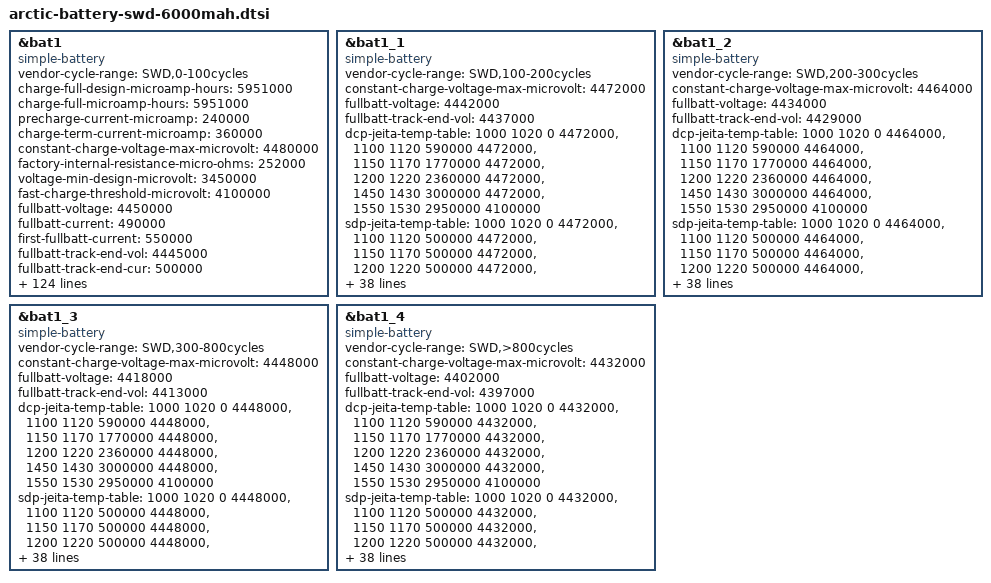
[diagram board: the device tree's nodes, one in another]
/* SWD aging 0--100 */
&bat1 {
	compatible = "simple-battery";
	status = "okay";
	vendor-cycle-range = "SWD,0-100cycles";
	charge-full-design-microamp-hours = <5951000>;
	charge-full-microamp-hours = <5951000>;
	precharge-current-microamp = <240000>;
	charge-term-current-microamp = <360000>;
	constant-charge-voltage-max-microvolt = <4480000>;
	factory-internal-resistance-micro-ohms = <252000>;
	voltage-min-design-microvolt = <3450000>;

	fast-charge-threshold-microvolt = <4100000>;
	fullbatt-voltage = <4450000>;
	fullbatt-current = <490000>;
	first-fullbatt-current = <550000>;
	fullbatt-track-end-vol = <4445000>;
	fullbatt-track-end-cur = <500000>;
	first-calib-voltage = <3580000>;
	first-calib-capacity = <50>;
	batt-ovp-threshold-microvolt = <4750000>;
	shutdown-voltage = <3150000>; //软件UVLO关机电压

	voltage-temp-table = <1119814 800>, <1007626 850>, <897107 900>,
				<791150 950>, <692012 1000>, <601214 1050>,
				<519546 1100>, <447188 1150>, <383853 1200>,
				<328947 1250>, <281696 1300>, <241249 1350>,
				<206756 1400>, <177412 1450>, <152480 1500>,
				<131307 1550>, <113324 1600>, <98032 1650>;

	temp-advance-fullcap-table = <50 100>, <25 100>, <10 100>, <0 100>,
		<(-10) 100>, <(-20) 100>;

	bcl-vbat-thres-celsius = <(-10)>, <0>, <10>, <25>, <45>;
	bcl-vbat-h-thres-0 = <3500>, <3400>;
	bcl-vbat-l-thres-0 = <3300>, <3200>;
	bcl-vbat-h-thres-1 = <3500>, <3400>;
	bcl-vbat-l-thres-1 = <3300>, <3200>;
	bcl-vbat-h-thres-2 = <3500>, <3400>;
	bcl-vbat-l-thres-2 = <3300>, <3200>;
	bcl-vbat-h-thres-3 = <3500>, <3400>;
	bcl-vbat-l-thres-3 = <3300>, <3200>;
	bcl-vbat-h-thres-4 = <3500>, <3400>;
	bcl-vbat-l-thres-4 = <3300>, <3200>;

	charge-sdp-current-microamp = <500000 500000>;
	charge-dcp-current-microamp = <2940000 1500000>;
	charge-cdp-current-microamp = <900000 900000>;
	charge-unknown-current-microamp = <1000000 1000000>;
	charge-fchg-current-microamp = <3000000 2000000>;
	charge-flash-current-microamp = <4900000 2700000>;
	charge-wl-bpp-current-microamp = <1000000 1000000>;
	charge-wl-epp-current-microamp = <2000000 1000000>;

	cap-calib-energy-density-ocv-table = <3400000 3690000>, <3890000 4480000>;

	dcp-jeita-temp-table = <1000 1020 0 4480000>, <1100 1120 590000 4480000>,
		<1150 1170 1770000 4480000>, <1200 1220 2360000 4480000>,
		<1450 1430 3000000 4480000>, <1550 1530 2950000 4100000>;
	sdp-jeita-temp-table = <1000 1020 0 4480000>, <1100 1120 500000 4480000>,
		<1150 1170 500000 4480000>, <1200 1220 500000 4480000>,
		<1450 1430 500000 4480000>, <1550 1530 500000 4100000>;
	cdp-jeita-temp-table = <1000 1020 0 4480000>, <1100 1120 590000 4480000>,
		<1150 1170 900000 4480000>, <1200 1220 900000 4480000>,
		<1450 1430 900000 4480000>, <1550 1530 900000 4100000>;
	unknown-jeita-temp-table = <1000 1020 0 4480000>, <1100 1120 590000 4480000>,
		<1150 1170 1000000 4480000>, <1200 1220 1000000 4480000>,
		<1450 1430 1000000 4480000>, <1550 1530 1000000 4100000>;
	fchg-jeita-temp-table = <1000 1020 0 4480000>, <1100 1120 590000 4480000>,
		<1150 1170 1770000 4480000>, <1200 1220 2360000 4480000>,
		<1450 1430 3000000 4480000>, <1550 1530 2950000 4100000>;
	flash-jeita-temp-table = <1000 1020 0 4480000>, <1100 1120 590000 4480000>,
		<1150 1170 1770000 4480000>, <1200 1220 2360000 4480000>,
		<1450 1430 3000000 4480000>, <1550 1530 2950000 4100000>;
	wl-bpp-jeita-temp-table = <1000 1020 0 4480000>, <1100 1120 500000 4480000>,
		<1150 1170 500000 4480000>, <1200 1220 500000 4480000>,
		<1450 1430 1000000 4480000>, <1550 1530 500000 4100000>;
	wl-epp-jeita-temp-table = <1000 1020 0 4480000>, <1100 1120 500000 4480000>,
		<1150 1170 500000 4480000>, <1200 1220 500000 4480000>,
		<1450 1430 2000000 4480000>, <1550 1530 500000 4100000>;


	bat-temp = <(-20)>, <(-10)>, <0>, <10>, <25>, <45>;

	/* temp-fcc */
	temp-fcc-fcc = <5438000>, <5611000>, <5841000>, <5904000>, <5951000>, <5891000>;

	/* temp-hc */
	temp-hc-hc = <20>, <20>, <20>, <10>, <10>, <10>;

	/* temp-zero-point-voltage */
	temp-zpvol-zpvol = <3430000>, <3430000>, <3430000>, <3450000>, <3450000>, <3450000>;
	/* temp-abs-zero-point-voltage */
	temp-abs-zpvol-zpvol = <3425000>, <3425000>, <3425000>, <3445000>, <3445000>, <3445000>;
	/* temp-bat-voltage */
	temp-batvol-batvol = <3570000>, <3570000>, <3570000>, <3580000>, <3580000>, <3580000>;

	/* cap-temp-ocv */
	cap-temp-ocv-cap = <100>, <99>, <98>, <97>, <96>, <95>, <94>, <93>, <92>, <91>, <90>,
			<89>, <88>, <87>, <86>, <85>, <84>, <83>, <82>, <81>, <80>,
			<79>, <78>, <77>, <76>, <75>, <74>, <73>, <72>, <71>, <70>,
			<69>, <68>, <67>, <66>, <65>, <64>, <63>, <62>, <61>, <60>,
			<59>, <58>, <57>, <56>, <55>, <54>, <53>, <52>, <51>, <50>,
			<49>, <48>, <47>, <46>, <45>, <44>, <43>, <42>, <41>, <40>,
			<39>, <38>, <37>, <36>, <35>, <34>, <33>, <32>, <31>, <30>,
			<29>, <28>, <27>, <26>, <25>, <24>, <23>, <22>, <21>, <20>,
			<19>, <18>, <17>, <16>, <15>, <14>, <13>, <12>, <11>, <10>,
			<9>, <8>, <7>, <6>, <5>, <4>, <3>, <2>, <1>, <0>;
	cap-temp-ocv-ocv = <
			/* -20 celsius */
			4422000 4400000 4382000 4365000 4350000 4336000 4322000 4310000 4296000 4284000
			4271000 4259000 4247000 4236000 4224000 4213000 4202000 4191000 4181000 4170000
			4160000 4150000 4140000 4130000 4119000 4109000 4099000 4088000 4078000 4067000
			4056000 4046000 4035000 4024000 4013000 4002000 3992000 3981000 3971000 3961000
			3951000 3941000 3931000 3922000 3912000 3904000 3896000 3888000 3880000 3872000
			3864000 3858000 3850000 3844000 3838000 3832000 3826000 3820000 3815000 3810000
			3806000 3802000 3798000 3794000 3790000 3788000 3784000 3782000 3778000 3775000
			3772000 3768000 3764000 3761000 3756000 3752000 3748000 3742000 3738000 3732000
			3726000 3718000 3711000 3703000 3694000 3686000 3676000 3665000 3655000 3644000
			3632000 3620000 3608000 3596000 3584000 3573000 3562000 3548000 3532000 3516000
			3500000
			/* -10 celsius */
			4426000 4408000 4392000 4378000 4365000 4352000 4340000 4328000 4315000 4303000
			4290000 4278000 4266000 4254000 4242000 4231000 4220000 4208000 4198000 4187000
			4176000 4166000 4156000 4145000 4134000 4124000 4113000 4102000 4092000 4081000
			4070000 4060000 4050000 4038000 4028000 4018000 4006000 3996000 3986000 3975000
			3964000 3954000 3943000 3932000 3922000 3913000 3904000 3894000 3886000 3878000
			3870000 3863000 3856000 3849000 3843000 3837000 3832000 3826000 3821000 3816000
			3811000 3807000 3803000 3799000 3795000 3792000 3789000 3787000 3784000 3782000
			3780000 3778000 3776000 3774000 3771000 3768000 3766000 3762000 3759000 3755000
			3750000 3745000 3739000 3732000 3724000 3715000 3704000 3690000 3676000 3659000
			3641000 3623000 3605000 3587000 3569000 3551000 3533000 3517000 3503000 3489000
			3473000
			/* 0 celsius */
			4427000 4410000 4396000 4382000 4370000 4358000 4346000 4332000 4320000 4307000
			4294000 4282000 4268000 4256000 4244000 4232000 4220000 4208000 4196000 4186000
			4174000 4164000 4152000 4142000 4130000 4120000 4108000 4098000 4086000 4076000
			4065000 4054000 4044000 4034000 4024000 4014000 4004000 3994000 3984000 3974000
			3964000 3954000 3944000 3932000 3921000 3910000 3898000 3888000 3880000 3872000
			3864000 3856000 3850000 3844000 3838000 3832000 3828000 3822000 3818000 3814000
			3809000 3805000 3801000 3798000 3794000 3792000 3788000 3786000 3784000 3782000
			3781000 3780000 3778000 3776000 3775000 3773000 3770000 3768000 3765000 3761000
			3756000 3751000 3744000 3738000 3730000 3718000 3704000 3686000 3665000 3641000
			3618000 3595000 3572000 3552000 3536000 3520000 3504000 3488000 3471000 3450000
			3418000
			/* 10 celsius */
			4432000 4416000 4402000 4388000 4376000 4363000 4350000 4338000 4325000 4312000
			4299000 4286000 4274000 4261000 4248000 4236000 4224000 4212000 4200000 4189000
			4178000 4166000 4155000 4144000 4133000 4122000 4110000 4100000 4088000 4078000
			4067000 4056000 4046000 4036000 4026000 4016000 4006000 3996000 3988000 3978000
			3968000 3960000 3950000 3939000 3928000 3916000 3904000 3892000 3882000 3874000
			3866000 3858000 3852000 3846000 3840000 3835000 3830000 3825000 3820000 3816000
			3812000 3808000 3804000 3801000 3798000 3794000 3792000 3790000 3787000 3785000
			3784000 3782000 3781000 3779000 3778000 3776000 3774000 3771000 3768000 3764000
			3759000 3754000 3750000 3744000 3739000 3732000 3723000 3712000 3698000 3680000
			3659000 3632000 3604000 3581000 3564000 3548000 3532000 3516000 3496000 3465000
			3412000
			/* 25 celsius */
			4432000 4414000 4400000 4386000 4373000 4360000 4348000 4334000 4322000 4308000
			4295000 4282000 4270000 4256000 4244000 4232000 4220000 4208000 4196000 4186000
			4174000 4162000 4152000 4140000 4128000 4118000 4106000 4096000 4084000 4074000
			4064000 4052000 4042000 4032000 4022000 4012000 4004000 3994000 3985000 3976000
			3968000 3958000 3950000 3940000 3930000 3916000 3904000 3891000 3881000 3872000
			3866000 3858000 3852000 3847000 3842000 3836000 3832000 3827000 3822000 3818000
			3814000 3811000 3808000 3804000 3801000 3798000 3796000 3794000 3791000 3789000
			3787000 3786000 3784000 3782000 3778000 3774000 3771000 3768000 3764000 3760000
			3756000 3752000 3749000 3746000 3742000 3736000 3729000 3722000 3716000 3708000
			3696000 3686000 3671000 3648000 3619000 3594000 3572000 3550000 3521000 3469000
			3400000
			/* 45 celsius */
			4421000 4403000 4388000 4374000 4360000 4347000 4333000 4320000 4307000 4294000
			4281000 4268000 4256000 4243000 4231000 4219000 4208000 4196000 4185000 4174000
			4163000 4152000 4141000 4130000 4119000 4108000 4097000 4086000 4076000 4065000
			4054000 4044000 4034000 4024000 4015000 4005000 3996000 3987000 3978000 3970000
			3961000 3953000 3944000 3935000 3924000 3910000 3897000 3886000 3877000 3870000
			3863000 3857000 3851000 3846000 3840000 3835000 3830000 3826000 3822000 3818000
			3813000 3810000 3806000 3803000 3799000 3796000 3794000 3791000 3789000 3786000
			3784000 3783000 3780000 3776000 3769000 3763000 3759000 3755000 3752000 3748000
			3744000 3740000 3737000 3734000 3730000 3724000 3718000 3711000 3705000 3697000
			3688000 3681000 3672000 3656000 3632000 3604000 3580000 3556000 3522000 3468000
			3400000
			>;


	/* cap-temp-resist */
	cap-temp-resist-cap = <100>, <99>, <98>, <97>, <96>, <95>, <94>, <93>, <92>, <91>, <90>,
			<89>, <88>, <87>, <86>, <85>, <84>, <83>, <82>, <81>, <80>,
			<79>, <78>, <77>, <76>, <75>, <74>, <73>, <72>, <71>, <70>,
			<69>, <68>, <67>, <66>, <65>, <64>, <63>, <62>, <61>, <60>,
			<59>, <58>, <57>, <56>, <55>, <54>, <53>, <52>, <51>, <50>,
			<49>, <48>, <47>, <46>, <45>, <44>, <43>, <42>, <41>, <40>,
			<39>, <38>, <37>, <36>, <35>, <34>, <33>, <32>, <31>, <30>,
			<29>, <28>, <27>, <26>, <25>, <24>, <23>, <22>, <21>, <20>,
			<19>, <18>, <17>, <16>, <15>, <14>, <13>, <12>, <11>, <10>,
			<9>, <8>, <7>, <6>, <5>, <4>, <3>, <2>, <1>, <0>;
	cap-temp-resist-resist = <
		  /* -20 celsius m o */
			694  694  730  734  730  727  720  712  708  703
			696  691  686  681  676  670  668  664  657  658
			655  653  648  645  645  644  644  648  652  650
			648  643  643  645  640  640  637  636  634  630
			634  633  630  624  630  630  630  629  628  632
			634  632  634  636  634  642  644  646  648  654
			660  666  672  678  681  692  700  710  718  727
			737  749  760  770  780  799  812  828  838  848
			862  880  896  912  931  944  963  990 1022 1059
			1111 1188 1299 1469 1754 2236 2656 2660 2670 2690
			2710
		  /* -10 celsius */
			384  384  394  401  404  404  402  398  395  391
			388  385  380  376  373  372  368  366  364  362
			361  359  358  357  356  356  355  356  356  356
			356  356  357  357  356  356  354  352  352  350
			346  344  340  336  334  330  327  324  322  320
			320  320  320  321  322  322  324  326  326  328
			329  330  332  334  336  339  343  346  352  358
			363  369  375  382  390  400  409  418  430  441
			453  466  478  492  505  517  530  541  552  565
			580  602  638  698  822 1154 2188 2547 2560 2600
			2650
		  /* 0 celsius */
			192  192  192  190  188  186  185  184  182  180
			179  178  176  174  174  172  172  170  169  170
			170  170  171  170  172  172  173  173  174  176
			176  178  179  180  182  184  184  186  187  188
			188  186  184  180  176  172  166  163  160  158
			157  158  158  157  157  158  158  158  159  160
			160  162  162  164  164  165  165  166  169  170
			172  175  178  180  182  186  188  192  194  199
			203  208  214  222  232  243  253  261  262  262
			260  262  269  284  316  396  756 1824 2437 2437
			2437
		  /* 10 celsius */
			126 126 126 126 126 125 124 124 123 122
			121 122 120 120 120 119 119 120 119 119
			118 118 119 120 120 120 120 122 123 124
			124 126 127 128 130 131 132 135 136 138
			139 140 141 140 136 131 126 120 116 115
			113 113 112 113 114 113 113 113 114 114
			116 115 116 118 118 118 119 119 120 121
			122 123 124 124 126 127 127 128 129 130
			130 131 134 136 140 146 151 158 166 172
			174 170 166 164 164 169 179 198 245 419
			1246
		  /* 25 celsius */
			80  80  80  80  80  79  80  80  79  78
			79  79  78  80  79  78  80  79  80  79
			80  80  79  80  80  81  81  82  82  83
			84  84  85  86  87  88  90  91  92  93
			96  98  99 100  98  94  88  83  80  79
			78  78  78  78  79  80  79  80  80  80
			80  80  80  81  82  82  82  83  83  84
			85  86  86  86  84  82  81  80  80  80
			81  80  82  83  84  84  85  86  88  91
			94 100 100 101 100 100  98 100  99 100
			105
		  /* 45 celsius */
			63 63 64 65 64 66 65 66 66 66
			67 66 66 68 68 67 68 68 68 68
			68 68 68 68 69 70 70 70 70 71
			70 72 72 73 74 74 76 76 78 78
			79 80 82 84 82 76 72 70 70 69
			70 70 70 70 70 70 69 70 70 71
			70 71 72 72 72 72 72 74 74 76
			76 78 78 74 70 70 71 71 71 72
			72 72 72 72 72 73 72 73 74 74
			75 78 78 78 80 82 82 82 80 81
			83
		>;
	cap-temp-resist-cycle = <300>, <600>;
	cap-temp-resist-ratio-0 = <
		  /* -20 celsius m o */
		  1030 1030 1030 1030 1030 1030 1030 1030 1030 1030 1040
		  1050 1050 1050 1060 1060 1060 1060 1060 1060 1060 1060
		  1060 1060 1060 1060 1060 1060 1060 1060 1060 1060 1060
		  1060 1060 1060 1060 1060 1060 1060 1060 1060 1060 1060
		  1060 1060 1060 1060 1060 1060 1060 1060 1060 1060 1060
		  1060 1060 1060 1060 1060 1060 1060 1060 1060 1050 1050
		  1050 1050 1050 1050 1050 1050 1050 1050 1050 1050 1050
		  1050 1050 1050 1050 1050 1050 1050 1050 1050 1050 1050
		  1050 1050 1050 1050 1050 1050 1050 1050 1050 1050 1050
		  1050 1050
		  /* -10 celsius */
		  1050 1050 1050 1050 1050 1050 1050 1050 1050 1050 1050
		  1050 1050 1050 1050 1050 1050 1050 1050 1050 1050 1050
		  1050 1050 1050 1050 1050 1050 1050 1050 1050 1050 1050
		  1050 1050 1050 1050 1050 1050 1050 1050 1050 1050 1050
		  1050 1050 1050 1050 1050 1050 1050 1050 1050 1050 1050
		  1050 1050 1050 1050 1050 1050 1050 1050 1050 1050 1050
		  1050 1050 1050 1050 1050 1050 1050 1050 1050 1050 1050
		  1050 1050 1050 1050 1050 1050 1050 1050 1050 1050 1050
		  1050 1050 1050 1050 1050 1050 1050 1050 1050 1050 1050
		  1050 1050
		  /* 0 celsius */
		  1160 1160 1160 1160 1160 1160 1160 1160 1170 1170 1170
		  1170 1170 1170 1170 1170 1170 1170 1170 1170 1170 1170
		  1170 1170 1170 1170 1170 1170 1170 1170 1170 1170 1170
		  1170 1170 1170 1180 1180 1180 1180 1180 1180 1180 1180
		  1180 1180 1190 1190 1190 1190 1190 1190 1190 1190 1190
		  1190 1190 1190 1190 1190 1190 1190 1190 1190 1190 1190
		  1190 1200 1200 1210 1220 1220 1220 1220 1220 1220 1230
		  1230 1230 1230 1230 1230 1230 1230 1230 1230 1230 1230
		  1230 1230 1230 1230 1250 1270 1290 1320 1350 1370 1400
		  1430 1430
		  /* 10 celsius */
		  1270 1270 1270 1270 1270 1270 1270 1270 1270 1280 1280
		  1280 1280 1290 1290 1290 1290 1290 1290 1290 1290 1290
		  1290 1300 1300 1300 1300 1300 1300 1300 1300 1300 1300
		  1300 1310 1310 1310 1310 1310 1310 1310 1310 1310 1310
		  1320 1320 1320 1320 1320 1320 1320 1320 1320 1320 1320
		  1320 1320 1330 1330 1330 1330 1330 1330 1330 1330 1330
		  1330 1330 1330 1330 1340 1340 1340 1340 1340 1340 1350
		  1360 1380 1400 1410 1430 1450 1470 1490 1500 1510 1520
		  1530 1530 1530 1530 1530 1530 1530 1530 1530 1530 1530
		  1530 1530
		  /* 25 celsius */
		  1110 1110 1110 1110 1110 1110 1110 1120 1120 1120 1130
		  1130 1140 1140 1140 1140 1140 1130 1130 1130 1130 1130
		  1130 1120 1120 1120 1120 1120 1120 1120 1120 1120 1120
		  1130 1130 1130 1130 1130 1140 1140 1140 1140 1140 1150
		  1150 1160 1160 1160 1160 1160 1160 1160 1160 1150 1150
		  1150 1150 1150 1160 1160 1160 1160 1160 1160 1150 1150
		  1150 1150 1150 1160 1160 1160 1160 1160 1160 1160 1160
		  1160 1160 1160 1160 1160 1160 1160 1160 1160 1150 1150
		  1150 1150 1150 1150 1150 1160 1160 1160 1160 1160 1160
		  1160 1160
		  /* 45 celsius */
		  1260 1260 1260 1260 1260 1260 1260 1270 1280 1290 1300
		  1300 1300 1300 1300 1300 1300 1300 1300 1300 1300 1300
		  1290 1290 1280 1270 1280 1290 1300 1310 1310 1310 1310
		  1310 1310 1310 1310 1310 1310 1310 1310 1310 1300 1290
		  1280 1270 1270 1270 1270 1270 1290 1290 1290 1290 1300
		  1310 1310 1310 1310 1310 1310 1310 1310 1300 1290 1290
		  1290 1290 1290 1300 1310 1310 1320 1320 1320 1320 1320
		  1320 1320 1320 1320 1320 1320 1320 1320 1320 1320 1310
		  1310 1310 1310 1310 1310 1310 1310 1320 1320 1320 1320
		  1320 1320
		>;

	cap-temp-resist-ratio-1 = <
		  /* -20 celsius m o */
		  1160 1160 1160 1160 1160 1160 1160 1160 1160 1170 1170
		  1180 1180 1190 1190 1190 1190 1200 1200 1210 1210 1210
		  1220 1220 1230 1230 1240 1250 1260 1270 1270 1270 1280
		  1290 1300 1310 1320 1340 1360 1380 1400 1400 1430 1460
		  1490 1520 1520 1520 1550 1590 1630 1660 1660 1690 1720
		  1750 1770 1770 1770 1770 1770 1770 1770 1770 1770 1770
		  1770 1770 1770 1770 1770 1770 1770 1770 1770 1770 1770
		  1770 1770 1770 1770 1770 1770 1770 1770 1770 1770 1770
		  1770 1770 1770 1770 1770 1770 1770 1770 1770 1770 1770
		  1770 1770
		  /* -10 celsius */
		  1180 1180 1180 1180 1180 1180 1180 1180 1170 1170 1170
		  1170 1170 1170 1170 1170 1170 1170 1170 1170 1170 1170
		  1170 1170 1170 1170 1170 1170 1170 1170 1170 1170 1170
		  1170 1170 1170 1170 1170 1170 1170 1170 1170 1170 1190
		  1190 1190 1190 1190 1200 1200 1200 1200 1200 1210 1210
		  1210 1210 1210 1210 1220 1240 1250 1270 1290 1290 1290
		  1290 1290 1290 1290 1300 1310 1320 1330 1340 1350 1350
		  1350 1370 1390 1410 1420 1440 1440 1460 1480 1500 1530
		  1550 1570 1590 1610 1620 1620 1620 1620 1620 1620 1620
		  1620 1620
		  /* 0 celsius */
		  1420 1420 1420 1420 1420 1420 1420 1420 1410 1410 1410
		  1410 1410 1410 1410 1410 1410 1410 1410 1410 1410 1410
		  1400 1400 1400 1400 1400 1400 1400 1400 1400 1400 1400
		  1400 1400 1400 1400 1400 1400 1400 1400 1400 1410 1410
		  1410 1410 1420 1420 1420 1420 1420 1420 1420 1420 1420
		  1420 1430 1430 1430 1430 1430 1430 1450 1450 1450 1450
		  1450 1450 1500 1500 1500 1500 1500 1500 1530 1530 1530
		  1530 1530 1530 1550 1550 1550 1550 1610 1610 1610 1610
		  1650 1700 1750 1800 1850 1900 1900 1900 1900 1900 1900
		  1900 1900
		  /* 10 celsius */
		  1400 1400 1400 1400 1400 1400 1400 1400 1400 1420 1420
		  1420 1420 1420 1420 1420 1420 1420 1420 1420 1420 1420
		  1420 1420 1420 1420 1420 1420 1410 1410 1410 1410 1410
		  1410 1410 1410 1410 1410 1410 1410 1410 1410 1410 1410
		  1410 1420 1420 1420 1420 1430 1430 1430 1430 1430 1420
		  1430 1430 1430 1430 1430 1430 1430 1430 1430 1430 1430
		  1430 1430 1430 1430 1470 1470 1470 1470 1470 1530 1530
		  1530 1530 1530 1590 1590 1590 1590 1630 1680 1710 1710
		  1780 1840 1900 1950 2000 2050 2100 2150 2200 2250 2250
		  2250 2250
		  /* 25 celsius */
		  1320 1320 1320 1320 1320 1320 1320 1320 1320 1320 1320
		  1320 1310 1310 1310 1310 1310 1310 1300 1300 1300 1300
		  1300 1290 1290 1290 1290 1290 1280 1280 1280 1280 1280
		  1280 1280 1280 1280 1280 1280 1280 1280 1280 1280 1290
		  1290 1300 1310 1310 1310 1310 1310 1310 1310 1310 1310
		  1310 1310 1310 1310 1310 1310 1310 1310 1310 1310 1310
		  1310 1310 1310 1310 1310 1310 1310 1320 1330 1340 1350
		  1350 1360 1360 1360 1360 1360 1370 1370 1370 1380 1390
		  1400 1410 1420 1430 1450 1460 1460 1460 1460 1460 1460
		  1460 1460
		  /* 45 celsius */
		  1298 1298 1298 1298 1298 1298 1298 1308 1318 1329 1339
		  1339 1339 1339 1339 1339 1339 1339 1339 1339 1339 1339
		  1329 1329 1318 1308 1318 1329 1339 1349 1349 1349 1349
		  1349 1349 1349 1349 1349 1349 1349 1349 1349 1339 1329
		  1318 1308 1308 1308 1308 1308 1329 1329 1329 1329 1339
		  1349 1349 1349 1349 1349 1349 1349 1349 1339 1329 1329
		  1329 1329 1329 1339 1349 1349 1360 1360 1360 1360 1360
		  1360 1360 1360 1360 1360 1360 1360 1360 1360 1360 1349
		  1349 1349 1349 1349 1349 1349 1349 1360 1360 1360 1360
		  1360 1360
		>;
};

/* SWD aging 100--200 */
&bat1_1 {
	compatible = "simple-battery";
	status = "okay";
	vendor-cycle-range = "SWD,100-200cycles";
	constant-charge-voltage-max-microvolt = <4472000>;
	fullbatt-voltage = <4442000>;
	fullbatt-track-end-vol = <4437000>;

	dcp-jeita-temp-table = <1000 1020 0 4472000>, <1100 1120 590000 4472000>,
		<1150 1170 1770000 4472000>, <1200 1220 2360000 4472000>,
		<1450 1430 3000000 4472000>, <1550 1530 2950000 4100000>;
	sdp-jeita-temp-table = <1000 1020 0 4472000>, <1100 1120 500000 4472000>,
		<1150 1170 500000 4472000>, <1200 1220 500000 4472000>,
		<1450 1430 500000 4472000>, <1550 1530 500000 4100000>;
	cdp-jeita-temp-table = <1000 1020 0 4472000>, <1100 1120 590000 4472000>,
		<1150 1170 900000 4472000>, <1200 1220 900000 4472000>,
		<1450 1430 900000 4472000>, <1550 1530 900000 4100000>;
	unknown-jeita-temp-table = <1000 1020 0 4472000>, <1100 1120 590000 4472000>,
		<1150 1170 1000000 4472000>, <1200 1220 1000000 4472000>,
		<1450 1430 1000000 4472000>, <1550 1530 1000000 4100000>;
	fchg-jeita-temp-table = <1000 1020 0 4472000>, <1100 1120 590000 4472000>,
		<1150 1170 1770000 4472000>, <1200 1220 2360000 4472000>,
		<1450 1430 3000000 4472000>, <1550 1530 2950000 4100000>;
	flash-jeita-temp-table = <1000 1020 0 4472000>, <1100 1120 590000 4472000>,
		<1150 1170 1770000 4472000>, <1200 1220 2360000 4472000>,
		<1450 1430 3000000 4472000>, <1550 1530 2950000 4100000>;
	wl-bpp-jeita-temp-table = <1000 1020 0 4472000>, <1100 1120 500000 4472000>,
		<1150 1170 500000 4472000>, <1200 1220 500000 4472000>,
		<1450 1430 1000000 4472000>, <1550 1530 500000 4100000>;
	wl-epp-jeita-temp-table = <1000 1020 0 4472000>, <1100 1120 500000 4472000>,
		<1150 1170 500000 4472000>, <1200 1220 500000 4472000>,
		<1450 1430 2000000 4472000>, <1550 1530 500000 4100000>;
};

/* SWD aging 200--300 */
&bat1_2 {
	compatible = "simple-battery";
	status = "okay";
	vendor-cycle-range = "SWD,200-300cycles";
	constant-charge-voltage-max-microvolt = <4464000>;
	fullbatt-voltage = <4434000>;
	fullbatt-track-end-vol = <4429000>;

	dcp-jeita-temp-table = <1000 1020 0 4464000>, <1100 1120 590000 4464000>,
		<1150 1170 1770000 4464000>, <1200 1220 2360000 4464000>,
		<1450 1430 3000000 4464000>, <1550 1530 2950000 4100000>;
	sdp-jeita-temp-table = <1000 1020 0 4464000>, <1100 1120 500000 4464000>,
		<1150 1170 500000 4464000>, <1200 1220 500000 4464000>,
		<1450 1430 500000 4464000>, <1550 1530 500000 4100000>;
	cdp-jeita-temp-table = <1000 1020 0 4464000>, <1100 1120 590000 4464000>,
		<1150 1170 900000 4464000>, <1200 1220 900000 4464000>,
		<1450 1430 900000 4464000>, <1550 1530 900000 4100000>;
	unknown-jeita-temp-table = <1000 1020 0 4464000>, <1100 1120 590000 4464000>,
		<1150 1170 1000000 4464000>, <1200 1220 1000000 4464000>,
		<1450 1430 1000000 4464000>, <1550 1530 1000000 4100000>;
	fchg-jeita-temp-table = <1000 1020 0 4464000>, <1100 1120 590000 4464000>,
		<1150 1170 1770000 4464000>, <1200 1220 2360000 4464000>,
		<1450 1430 3000000 4464000>, <1550 1530 2950000 4100000>;
	flash-jeita-temp-table = <1000 1020 0 4464000>, <1100 1120 590000 4464000>,
		<1150 1170 1770000 4464000>, <1200 1220 2360000 4464000>,
		<1450 1430 3000000 4464000>, <1550 1530 2950000 4100000>;
	wl-bpp-jeita-temp-table = <1000 1020 0 4464000>, <1100 1120 500000 4464000>,
		<1150 1170 500000 4464000>, <1200 1220 500000 4464000>,
		<1450 1430 1000000 4464000>, <1550 1530 500000 4100000>;
	wl-epp-jeita-temp-table = <1000 1020 0 4464000>, <1100 1120 500000 4464000>,
		<1150 1170 500000 4464000>, <1200 1220 500000 4464000>,
		<1450 1430 2000000 4464000>, <1550 1530 500000 4100000>;
};

/* SWD aging 300--800 */
&bat1_3 {
	compatible = "simple-battery";
	status = "okay";
	vendor-cycle-range = "SWD,300-800cycles";
	constant-charge-voltage-max-microvolt = <4448000>;
	fullbatt-voltage = <4418000>;
	fullbatt-track-end-vol = <4413000>;

	dcp-jeita-temp-table = <1000 1020 0 4448000>, <1100 1120 590000 4448000>,
		<1150 1170 1770000 4448000>, <1200 1220 2360000 4448000>,
		<1450 1430 3000000 4448000>, <1550 1530 2950000 4100000>;
	sdp-jeita-temp-table = <1000 1020 0 4448000>, <1100 1120 500000 4448000>,
		<1150 1170 500000 4448000>, <1200 1220 500000 4448000>,
		<1450 1430 500000 4448000>, <1550 1530 500000 4100000>;
	cdp-jeita-temp-table = <1000 1020 0 4448000>, <1100 1120 590000 4448000>,
		<1150 1170 900000 4448000>, <1200 1220 900000 4448000>,
		<1450 1430 900000 4448000>, <1550 1530 900000 4100000>;
	unknown-jeita-temp-table = <1000 1020 0 4448000>, <1100 1120 590000 4448000>,
		<1150 1170 1000000 4448000>, <1200 1220 1000000 4448000>,
		<1450 1430 1000000 4448000>, <1550 1530 1000000 4100000>;
	fchg-jeita-temp-table = <1000 1020 0 4448000>, <1100 1120 590000 4448000>,
		<1150 1170 1770000 4448000>, <1200 1220 2360000 4448000>,
		<1450 1430 3000000 4448000>, <1550 1530 2950000 4100000>;
	flash-jeita-temp-table = <1000 1020 0 4448000>, <1100 1120 590000 4448000>,
		<1150 1170 1770000 4448000>, <1200 1220 2360000 4448000>,
		<1450 1430 3000000 4448000>, <1550 1530 2950000 4100000>;
	wl-bpp-jeita-temp-table = <1000 1020 0 4448000>, <1100 1120 500000 4448000>,
		<1150 1170 500000 4448000>, <1200 1220 500000 4448000>,
		<1450 1430 1000000 4448000>, <1550 1530 500000 4100000>;
	wl-epp-jeita-temp-table = <1000 1020 0 4448000>, <1100 1120 500000 4448000>,
		<1150 1170 500000 4448000>, <1200 1220 500000 4448000>,
		<1450 1430 2000000 4448000>, <1550 1530 500000 4100000>;
};

/* SWD aging > 800 */
&bat1_4 {
	compatible = "simple-battery";
	status = "okay";
	vendor-cycle-range = "SWD,>800cycles";
	constant-charge-voltage-max-microvolt = <4432000>;
	fullbatt-voltage = <4402000>;
	fullbatt-track-end-vol = <4397000>;

	dcp-jeita-temp-table = <1000 1020 0 4432000>, <1100 1120 590000 4432000>,
		<1150 1170 1770000 4432000>, <1200 1220 2360000 4432000>,
		<1450 1430 3000000 4432000>, <1550 1530 2950000 4100000>;
	sdp-jeita-temp-table = <1000 1020 0 4432000>, <1100 1120 500000 4432000>,
		<1150 1170 500000 4432000>, <1200 1220 500000 4432000>,
		<1450 1430 500000 4432000>, <1550 1530 500000 4100000>;
	cdp-jeita-temp-table = <1000 1020 0 4432000>, <1100 1120 590000 4432000>,
		<1150 1170 900000 4432000>, <1200 1220 900000 4432000>,
		<1450 1430 900000 4432000>, <1550 1530 900000 4100000>;
	unknown-jeita-temp-table = <1000 1020 0 4432000>, <1100 1120 590000 4432000>,
		<1150 1170 1000000 4432000>, <1200 1220 1000000 4432000>,
		<1450 1430 1000000 4432000>, <1550 1530 1000000 4100000>;
	fchg-jeita-temp-table = <1000 1020 0 4432000>, <1100 1120 590000 4432000>,
		<1150 1170 1770000 4432000>, <1200 1220 2360000 4432000>,
		<1450 1430 3000000 4432000>, <1550 1530 2950000 4100000>;
	flash-jeita-temp-table = <1000 1020 0 4432000>, <1100 1120 590000 4432000>,
		<1150 1170 1770000 4432000>, <1200 1220 2360000 4432000>,
		<1450 1430 3000000 4432000>, <1550 1530 2950000 4100000>;
	wl-bpp-jeita-temp-table = <1000 1020 0 4432000>, <1100 1120 500000 4432000>,
		<1150 1170 500000 4432000>, <1200 1220 500000 4432000>,
		<1450 1430 1000000 4432000>, <1550 1530 500000 4100000>;
	wl-epp-jeita-temp-table = <1000 1020 0 4432000>, <1100 1120 500000 4432000>,
		<1150 1170 500000 4432000>, <1200 1220 500000 4432000>,
		<1450 1430 2000000 4432000>, <1550 1530 500000 4100000>;
};
